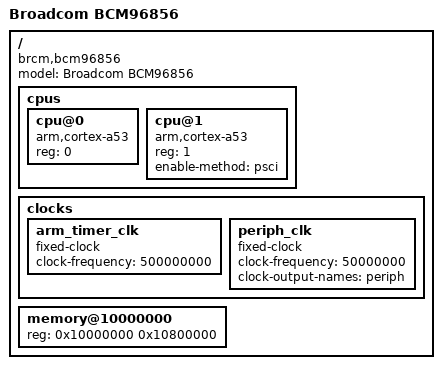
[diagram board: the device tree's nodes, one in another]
/*
 * Broadcom BCM6856 DTS
 */

/dts-v1/;

/ {
    compatible = "brcm,bcm6856";
    model = "Broadcom BCM6856 PON SoC";

    cpus {
        #address-cells = <1>;
        #size-cells = <0>;

        cpu@0 {
            device_type = "cpu";
            compatible = "arm,cortex-a53";
            reg = <0>;
        };

        cpu@1 {
            device_type = "cpu";
            compatible = "arm,cortex-a53";
            reg = <1>;
            enable-method = "psci";
        };

    };

    clocks {
        #address-cells = <1>;
        #size-cells = <0>;

        arm_timer_clk: arm_timer_clk {
            #clock-cells = <0>;
            compatible = "fixed-clock";
            clock-frequency = <500000000>; 
        };

        periph_clk: periph_clk { 
            #clock-cells = <0>;
            compatible = "fixed-clock";
            clock-frequency = <50000000>;
            clock-output-names = "periph";
        };
    };
 };


/ {
    compatible = "brcm,bcm96856";
    model = "Broadcom BCM96856";
    #address-cells = <1>;
    #size-cells = <1>;

    memory@10000000 {
        device_type = "memory";
        /* First  entry: ATF load address
           Second entry: OPTEE load address
         */
        reg = <0x10000000 0x10800000>;
    };
};



